VERSION "100"

NS_ :

BS_:

BU_: C125

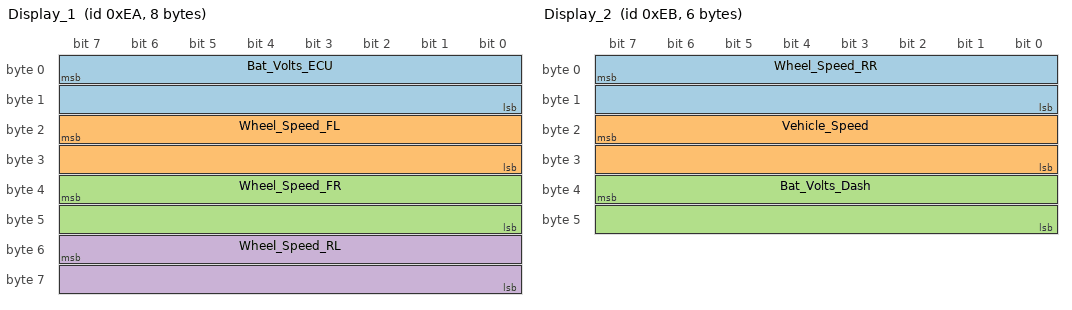
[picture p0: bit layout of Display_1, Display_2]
BO_ 234 Display_1: 8 C125
 SG_ Bat_Volts_ECU : 7|16@0- (0.01,0) [800|1500] "V"  Vector__XXX
 SG_ Wheel_Speed_FL : 23|16@0- (0.1,0) [0|3000] "km/h"  Vector__XXX
 SG_ Wheel_Speed_FR : 39|16@0- (0.1,0) [0|3000] "km/h"  Vector__XXX
 SG_ Wheel_Speed_RL : 55|16@0- (0.1,0) [0|3000] "km/h"  Vector__XXX

BO_ 235 Display_2: 6 C125
 SG_ Wheel_Speed_RR : 7|16@0- (0.1,0) [0|3000] "km/h"  Vector__XXX
 SG_ Vehicle_Speed : 23|16@0- (0.1,0) [0|3000] "km/h"  Vector__XXX
 SG_ Bat_Volts_Dash : 39|16@0- (0.01,0) [0|0] "V"  Vector__XXX

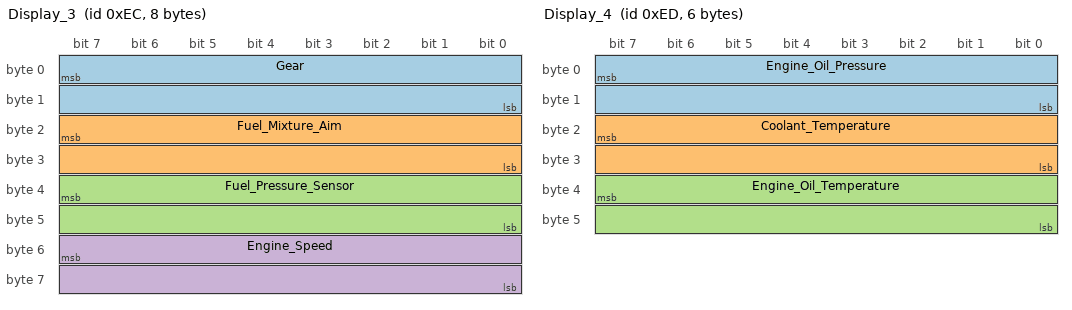
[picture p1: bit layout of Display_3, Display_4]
BO_ 236 Display_3: 8 C125
 SG_ Gear : 7|16@0- (1,0) [0|0] ""  Vector__XXX
 SG_ Fuel_Mixture_Aim : 23|16@0- (0.01,0) [0|0] "LA"  Vector__XXX
 SG_ Fuel_Pressure_Sensor : 39|16@0- (0.1,0) [0|0] "kPa"  Vector__XXX
 SG_ Engine_Speed : 55|16@0- (0.1,0) [0|0] "rps"  Vector__XXX

BO_ 237 Display_4: 6 C125
 SG_ Engine_Oil_Pressure : 7|16@0- (0.1,0) [0|0] "kPa"  Vector__XXX
 SG_ Coolant_Temperature : 23|16@0- (0.1,0) [0|0] "C"  Vector__XXX
 SG_ Engine_Oil_Temperature : 39|16@0- (0.1,0) [0|0] "C"  Vector__XXX

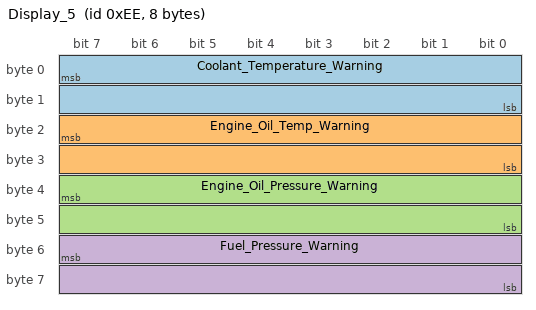
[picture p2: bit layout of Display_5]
BO_ 238 Display_5: 8 C125
 SG_ Coolant_Temperature_Warning : 7|16@0- (1,0) [0|0] ""  Vector__XXX
 SG_ Engine_Oil_Temp_Warning : 23|16@0- (1,0) [0|0] ""  Vector__XXX
 SG_ Engine_Oil_Pressure_Warning : 39|16@0- (1,0) [0|0] ""  Vector__XXX
 SG_ Fuel_Pressure_Warning : 55|16@0- (1,0) [0|0] ""  Vector__XXX

BO_ 239 Display_6: 4 C125
 SG_ Launch_Switch : 7|16@0- (1,0) [0|0] ""  Vector__XXX
 SG_ Launch_State : 23|16@0- (1,0) [0|0] ""  Vector__XXX

BO_ 240 Alarm_Message: 8 C125
 SG_ Alarm_Message : 7|64@0+ (0,0) [0|0] ""  Vector__XXX

BO_ 241 Alarm_Value: 8 C125
 SG_ Alarm_Value : 7|64@0+ (0,0) [0|0] ""  Vector__XXX

BO_ 242 Alarm_Status: 2 C125
 SG_ Alarm_Active : 7|8@0+ (0,0) [0|0] ""  Vector__XXX
 SG_ Alarm_Flash : 15|8@0+ (0,0) [0|0] ""  Vector__XXX

BO_ 233 CRC32: 4 C125
 SG_ CRC32 : 7|32@0+ (1,0) [0|0] ""  Vector__XXX

BA_DEF_  "MoTeC_CRC" INT 0 0;
BA_DEF_ SG_  "MoTeC_Type" ENUM  "Number","Compound_String";
BA_DEF_ SG_  "MoTeC_Usage" ENUM  "General","CRC32","Alarm_Message","Alarm_Value","Alarm_Active_State","Alarm_Flash_State";
BA_DEF_ SG_  "MoTeC_Channel" STRING ;
BA_DEF_ BO_  "GenMsgCycleTime" INT 0 0;
BA_DEF_DEF_  "MoTeC_CRC" -938415403;
BA_DEF_DEF_  "MoTeC_Type" "Number";
BA_DEF_DEF_  "MoTeC_Usage" "General";
BA_DEF_DEF_  "MoTeC_Channel" "";
BA_DEF_DEF_  "GenMsgCycleTime" 50;
BA_ "GenMsgCycleTime" BO_ 236 100;
BA_ "GenMsgCycleTime" BO_ 237 100;
BA_ "GenMsgCycleTime" BO_ 238 1000;
BA_ "GenMsgCycleTime" BO_ 239 1000;
BA_ "GenMsgCycleTime" BO_ 233 1000;
BA_ "MoTeC_Channel" SG_ 234 Bat_Volts_ECU "Bat Volts ECU";
BA_ "MoTeC_Channel" SG_ 234 Wheel_Speed_FL "Wheel Speed FL";
BA_ "MoTeC_Channel" SG_ 234 Wheel_Speed_FR "Wheel Speed FR";
BA_ "MoTeC_Channel" SG_ 234 Wheel_Speed_RL "Wheel Speed RL";
BA_ "MoTeC_Channel" SG_ 235 Wheel_Speed_RR "Wheel Speed RR";
BA_ "MoTeC_Channel" SG_ 235 Vehicle_Speed "Vehicle Speed";
BA_ "MoTeC_Channel" SG_ 235 Bat_Volts_Dash "Bat Volts Dash";
BA_ "MoTeC_Channel" SG_ 236 Gear "Gear";
BA_ "MoTeC_Channel" SG_ 236 Fuel_Mixture_Aim "Fuel Mixture Aim";
BA_ "MoTeC_Channel" SG_ 236 Fuel_Pressure_Sensor "Fuel Pressure Sensor";
BA_ "MoTeC_Channel" SG_ 236 Engine_Speed "Engine Speed";
BA_ "MoTeC_Channel" SG_ 237 Engine_Oil_Pressure "Engine Oil Pressure";
BA_ "MoTeC_Channel" SG_ 237 Coolant_Temperature "Coolant Temperature";
BA_ "MoTeC_Channel" SG_ 237 Engine_Oil_Temperature "Engine Oil Temperature";
BA_ "MoTeC_Channel" SG_ 238 Coolant_Temperature_Warning "Coolant Temperature Warning";
BA_ "MoTeC_Channel" SG_ 238 Engine_Oil_Temp_Warning "Engine Oil Temp Warning";
BA_ "MoTeC_Channel" SG_ 238 Engine_Oil_Pressure_Warning "Engine Oil Pressure Warning";
BA_ "MoTeC_Channel" SG_ 238 Fuel_Pressure_Warning "Fuel Pressure Warning";
BA_ "MoTeC_Channel" SG_ 239 Launch_Switch "Launch Switch";
BA_ "MoTeC_Channel" SG_ 239 Launch_State "Launch State";
BA_ "MoTeC_Type" SG_ 240 Alarm_Message 1;
BA_ "MoTeC_Usage" SG_ 240 Alarm_Message 2;
BA_ "MoTeC_Type" SG_ 241 Alarm_Value 1;
BA_ "MoTeC_Usage" SG_ 241 Alarm_Value 3;
BA_ "MoTeC_Usage" SG_ 242 Alarm_Active 4;
BA_ "MoTeC_Usage" SG_ 242 Alarm_Flash 5;
BA_ "MoTeC_Usage" SG_ 233 CRC32 1;
